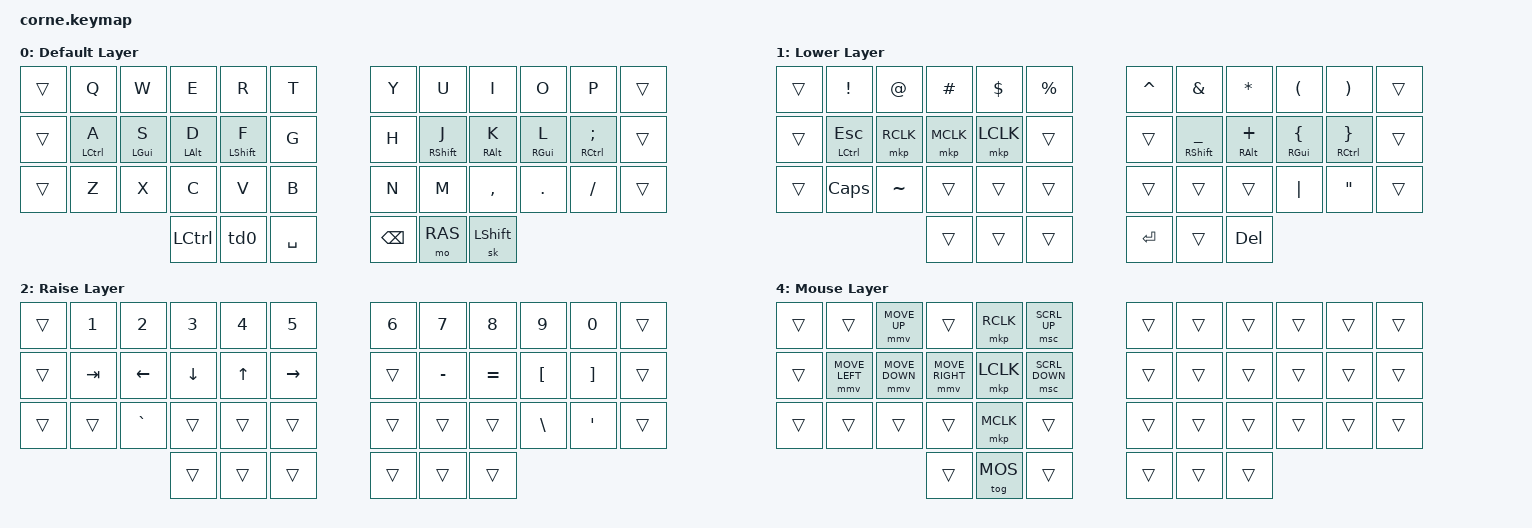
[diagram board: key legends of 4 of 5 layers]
/*
 * Copyright (c) 2020 The ZMK Contributors
 *
 * SPDX-License-Identifier: MIT
 */

#include <behaviors.dtsi>
#include <dt-bindings/zmk/keys.h>
#include <dt-bindings/zmk/bt.h>

#define ZMK_POINTING_DEFAULT_MOVE_VAL 1500  // default: 600
#define ZMK_POINTING_DEFAULT_SCRL_VAL 20    // default: 10

#include <dt-bindings/zmk/pointing.h>
#include <behaviors/anti_idle_mode.dtsi>
#include <dt-bindings/anti_idle_mode.h>

#define _BT_SEL_KEYS_ ___ &bt BT_SEL 0 &bt BT_SEL 1 &bt BT_SEL 2 &bt BT_SEL 3 &bt BT_SEL 4 &bt BT_CLR

#define DEF 0  // layer shortcuts, must match order in which they are defined below
#define LOW 1
#define RAS 2
#define FUN 3
#define MOS 4

#include "behaviors.dtsi"

#define ___ &trans

/ {
        anti_idle {
                compatible = "zmk,anti-idle-generic";
                interval-ms = <30000>;
                bindings = <&mmv MOVE_DOWN &mmv MOVE_UP>;
                tap_ms = <200>;
                wait_ms = <200>;
        };

        conditional_layers {
            compatible = "zmk,conditional-layers";
            tri_layer {
              if-layers = <LOW RAS>;
              then-layer = <FUN>;
            };
        };

        keymap {
                compatible = "zmk,keymap";

                default_layer {
                        display-name = "Default Layer";
                        bindings = <
     // ╭─────────────┬─────────────┬─────────────┬─────────────┬─────────────┬─────────────╮   ╭─────────────┬─────────────┬─────────────┬─────────────┬─────────────┬─────────────╮
             ___           &kp Q         &kp W         &kp E         &kp R         &kp T             &kp Y         &kp U         &kp I         &kp O         &kp P         ___
     // ├─────────────┼─────────────┼─────────────┼─────────────┼─────────────┼─────────────┤   ├─────────────┼─────────────┼─────────────┼─────────────┼─────────────┼─────────────┤
             ___       &hrm LCTRL A   &hrm LGUI S   &hrm LALT D  &hrm LSHFT F      &kp G             &kp H      &hrm RSHFT J  &hrm RALT K   &hrm RGUI L   &hrm RCTRL SEMI  ___
     // ├─────────────┼─────────────┼─────────────┼─────────────┼─────────────┼─────────────┤   ├─────────────┼─────────────┼─────────────┼─────────────┼─────────────┼─────────────┤
             ___            &kp Z         &kp X         &kp C         &kp V        &kp B             &kp N         &kp M       &kp COMMA     &kp DOT       &kp FSLH        ___
     // ╰─────────────┼─────────────┼─────────────┼─────────────┼─────────────┼─────────────┤   ├─────────────┼─────────────┼─────────────┼─────────────┼─────────────┼─────────────┤
                                                      &kp LCTRL       &td0         &kp SPACE         &kp BSPC      &mo RAS      &sk LSHFT
     //                                           ╰─────────────┴─────────────┴─────────────╯   ╰─────────────┴─────────────┴─────────────╯
                        >;
                };

                lower_layer {
                        display-name = "Lower Layer";
                        bindings = <
     // ╭─────────────┬─────────────┬─────────────┬─────────────┬─────────────┬─────────────╮   ╭─────────────┬─────────────┬─────────────┬─────────────┬─────────────┬─────────────╮
             ___         &kp EXCL      &kp AT        &kp HASH      &kp DLLR      &kp PRCNT         &kp CARET     &kp AMPS      &kp STAR      &kp LPAR      &kp RPAR        ___
     // ├─────────────┼─────────────┼─────────────┼─────────────┼─────────────┼─────────────┤   ├─────────────┼─────────────┼─────────────┼─────────────┼─────────────┼─────────────┤
             ___       &hrm LCTRL ESC  &mkp RCLK     &mkp MCLK     &mkp LCLK        ___               ___   &hrm RSHFT UNDER &hrm RALT PLUS &hrm RGUI LBRC &hrm RCTRL RBRC ___
     // ├─────────────┼─────────────┼─────────────┼─────────────┼─────────────┼─────────────┤   ├─────────────┼─────────────┼─────────────┼─────────────┼─────────────┼─────────────┤
             ___         &kp CAPS      &kp TILDE        ___           ___           ___               ___           ___           ___        &kp PIPE      &kp DQT         ___
     // ╰─────────────┼─────────────┼─────────────┼─────────────┼─────────────┼─────────────┤   ├─────────────┼─────────────┼─────────────┼─────────────┼─────────────┼─────────────┤
                                                        ___           ___           ___              &kp RET        ___        &kp DEL
     //                                           ╰─────────────┴─────────────┴─────────────╯   ╰─────────────┴─────────────┴─────────────╯
                        >;
                };

                raise_layer {
                        display-name = "Raise Layer";
                        bindings = <
     // ╭─────────────┬─────────────┬─────────────┬─────────────┬─────────────┬─────────────╮   ╭─────────────┬─────────────┬─────────────┬─────────────┬─────────────┬─────────────╮
             ___          &kp N1        &kp N2        &kp N3        &kp N4        &kp N5            &kp N6        &kp N7        &kp N8        &kp N9        &kp N0         ___
     // ├─────────────┼─────────────┼─────────────┼─────────────┼─────────────┼─────────────┤   ├─────────────┼─────────────┼─────────────┼─────────────┼─────────────┼─────────────┤
             ___          &kp TAB       &kp LEFT      &kp DOWN      &kp UP        &kp RIGHT           ___         &kp MINUS     &kp EQUAL     &kp LBKT      &kp RBKT       ___
     // ├─────────────┼─────────────┼─────────────┼─────────────┼─────────────┼─────────────┤   ├─────────────┼─────────────┼─────────────┼─────────────┼─────────────┼─────────────┤
             ___            ___         &kp GRAVE       ___           ___           ___               ___           ___           ___         &kp BSLH      &kp SQT        ___
     // ╰─────────────┼─────────────┼─────────────┼─────────────┼─────────────┼─────────────┤   ├─────────────┼─────────────┼─────────────┼─────────────┼─────────────┼─────────────┤
                                                        ___           ___           ___               ___           ___           ___
     //                                           ╰─────────────┴─────────────┴─────────────╯   ╰─────────────┴─────────────┴─────────────╯
                        >;
                };

                func_layer {
                        display-name = "Func Layer";
                        bindings = <
     // ╭─────────────┬─────────────┬─────────────┬─────────────┬─────────────┬─────────────╮   ╭─────────────┬─────────────┬─────────────┬─────────────┬─────────────┬─────────────╮
             ___           &kp F1        &kp F2        &kp F3        &kp F4        &kp F5            &kp F6        &kp F7        &kp F8        &kp F9        &kp F10       ___
     // ├─────────────┼─────────────┼─────────────┼─────────────┼─────────────┼─────────────┤   ├─────────────┼─────────────┼─────────────┼─────────────┼─────────────┼─────────────┤
             ___           &kp F11      &kp F12         ___       &sys_reset    &bootloader       &bootloader   &sys_reset    &aim AIM_TOG      ___           ___          ___
     // ├─────────────┼─────────────┼─────────────┼─────────────┼─────────────┼─────────────┤   ├─────────────┼─────────────┼─────────────┼─────────────┼─────────────┼─────────────┤
                                     _BT_SEL_KEYS_                                                                  ___           ___           ___           ___          ___
     // ╰─────────────┼─────────────┼─────────────┼─────────────┼─────────────┼─────────────┤   ├─────────────┼─────────────┼─────────────┼─────────────┼─────────────┼─────────────┤
                                                        ___           ___           ___               ___           ___           ___
     //                                           ╰─────────────┴─────────────┴─────────────╯   ╰─────────────┴─────────────┴─────────────╯
                        >;
                };

                mouse_layer {
                        display-name = "Mouse Layer";
                        bindings = <
     // ╭─────────────┬─────────────┬─────────────┬─────────────┬─────────────┬─────────────╮   ╭─────────────┬─────────────┬─────────────┬─────────────┬─────────────┬─────────────╮
             ___            ___        &mmv MOVE_UP       ___       &mkp RCLK  &msc SCRL_UP           ___           ___           ___           ___           ___          ___
     // ├─────────────┼─────────────┼─────────────┼─────────────┼─────────────┼─────────────┤   ├─────────────┼─────────────┼─────────────┼─────────────┼─────────────┼─────────────┤
             ___      &mmv MOVE_LEFT &mmv MOVE_DOWN &mmv MOVE_RIGHT &mkp LCLK  &msc SCRL_DOWN         ___           ___           ___           ___           ___          ___
     // ├─────────────┼─────────────┼─────────────┼─────────────┼─────────────┼─────────────┤   ├─────────────┼─────────────┼─────────────┼─────────────┼─────────────┼─────────────┤
             ___            ___           ___           ___         &mkp MCLK       ___               ___           ___           ___           ___           ___          ___
     // ╰─────────────┼─────────────┼─────────────┼─────────────┼─────────────┼─────────────┤   ├─────────────┼─────────────┼─────────────┼─────────────┼─────────────┼─────────────┤
                                                        ___          &tog MOS       ___               ___           ___           ___
     //                                           ╰─────────────┴─────────────┴─────────────╯   ╰─────────────┴─────────────┴─────────────╯
                        >;
                };
        };
};
